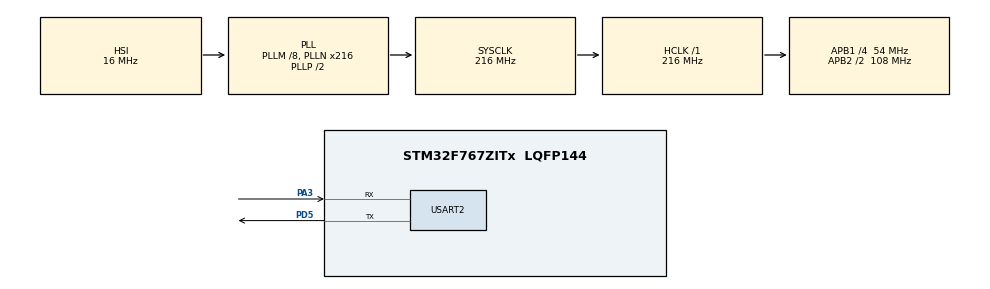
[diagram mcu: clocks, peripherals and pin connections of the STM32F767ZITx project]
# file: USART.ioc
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Dma.Request0=USART2_RX
Dma.USART2_RX.0.Direction=DMA_PERIPH_TO_MEMORY
Dma.USART2_RX.0.FIFOMode=DMA_FIFOMODE_DISABLE
Dma.USART2_RX.0.Instance=DMA1_Stream5
Dma.USART2_RX.0.MemDataAlignment=DMA_MDATAALIGN_BYTE
Dma.USART2_RX.0.MemInc=DMA_MINC_ENABLE
Dma.USART2_RX.0.Mode=DMA_CIRCULAR
Dma.USART2_RX.0.PeriphDataAlignment=DMA_PDATAALIGN_BYTE
Dma.USART2_RX.0.PeriphInc=DMA_PINC_DISABLE
Dma.USART2_RX.0.Priority=DMA_PRIORITY_LOW
Mcu.Family=STM32F7
Mcu.Name=STM32F767ZITx
Mcu.Package=LQFP144
NVIC.DMA1_Stream5_IRQn=true\:0\:0\:false\:false\:true\:false\:true
NVIC.PriorityGroup=NVIC_PRIORITYGROUP_4
NVIC.USART2_IRQn=true\:5\:0\:true\:false\:true\:true\:true
PA3.GPIO_PuPd=GPIO_PULLUP
PA3.Mode=Asynchronous
PA3.Signal=USART2_RX
PD5.Mode=Asynchronous
PD5.Signal=USART2_TX
ProjectManager.HeapSize=0x200
ProjectManager.StackSize=0x400
ProjectManager.TargetToolchain=STM32CubeIDE
RCC.AHBFreq_Value=216000000
RCC.APB1CLKDivider=RCC_HCLK_DIV4
RCC.APB1Freq_Value=54000000
RCC.APB1TimFreq_Value=108000000
RCC.APB2CLKDivider=RCC_HCLK_DIV2
RCC.APB2Freq_Value=108000000
RCC.APB2TimFreq_Value=216000000
RCC.CortexFreq_Value=216000000
RCC.HCLKFreq_Value=216000000
RCC.HSE_VALUE=25000000
RCC.HSI_VALUE=16000000
RCC.LSE_VALUE=32768
RCC.PLLM=8
RCC.PLLN=216
RCC.SYSCLKFreq_VALUE=216000000
RCC.SYSCLKSource=RCC_SYSCLKSOURCE_PLLCLK
RCC.USBFreq_Value=216000000
RCC.VCOOutputFreq_Value=432000000
USART2.VirtualMode-Asynchronous=VM_ASYNC
board=custom

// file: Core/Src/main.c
/* USER CODE BEGIN Header */
/**
  ******************************************************************************
  * @file           : main.c
  * @brief          : Main program body
  ******************************************************************************
  * @attention
  *
  * <h2><center>&copy; Copyright (c) 2021 STMicroelectronics.
  * All rights reserved.</center></h2>
  *
  * This software component is licensed by ST under BSD 3-Clause license,
  * the "License"; You may not use this file except in compliance with the
  * License. You may obtain a copy of the License at:
  *                        opensource.org/licenses/BSD-3-Clause
  *
  ******************************************************************************
  */
/* USER CODE END Header */
#include "main.h"
#include "dma.h"
#include "usart.h"
#include "gpio.h"

/* USER CODE BEGIN PV */
uint8_t receive_buff[255];
/* USER CODE END PV */

void SystemClock_Config(void);

int main(void)
{

  /* MCU Configuration--------------------------------------------------------*/

  /* Reset of all peripherals, Initializes the Flash interface and the Systick. */
  HAL_Init();

  /* Configure the system clock */
  SystemClock_Config();

  /* Initialize all configured peripherals */
  MX_GPIO_Init();
  MX_DMA_Init();
  MX_USART2_UART_Init();

  /* Infinite loop */
  /* USER CODE BEGIN WHILE */
  __HAL_UART_ENABLE_IT(&huart2, UART_IT_IDLE);
  HAL_UART_Receive_DMA(&huart2, (uint8_t*)receive_buff, 255); //transmit 255 byte, from uart to DMA

  while (1)
  {
    /* USER CODE END WHILE */

  }
}

void SystemClock_Config(void)
{
  RCC_OscInitTypeDef RCC_OscInitStruct = {0};
  RCC_ClkInitTypeDef RCC_ClkInitStruct = {0};
  RCC_PeriphCLKInitTypeDef PeriphClkInitStruct = {0};

  /** Configure the main internal regulator output voltage
  */
  __HAL_RCC_PWR_CLK_ENABLE();
  __HAL_PWR_VOLTAGESCALING_CONFIG(PWR_REGULATOR_VOLTAGE_SCALE1);
  /** Initializes the RCC Oscillators according to the specified parameters
  * in the RCC_OscInitTypeDef structure.
  */
  RCC_OscInitStruct.OscillatorType = RCC_OSCILLATORTYPE_HSI;
  RCC_OscInitStruct.HSIState = RCC_HSI_ON;
  RCC_OscInitStruct.HSICalibrationValue = RCC_HSICALIBRATION_DEFAULT;
  RCC_OscInitStruct.PLL.PLLState = RCC_PLL_ON;
  RCC_OscInitStruct.PLL.PLLSource = RCC_PLLSOURCE_HSI;
  RCC_OscInitStruct.PLL.PLLM = 8;
  RCC_OscInitStruct.PLL.PLLN = 216;
  RCC_OscInitStruct.PLL.PLLP = RCC_PLLP_DIV2;
  RCC_OscInitStruct.PLL.PLLQ = 2;
  if (HAL_RCC_OscConfig(&RCC_OscInitStruct) != HAL_OK)
  {
    Error_Handler();
  }
  /** Activate the Over-Drive mode
  */
  if (HAL_PWREx_EnableOverDrive() != HAL_OK)
  {
    Error_Handler();
  }
  /** Initializes the CPU, AHB and APB buses clocks
  */
  RCC_ClkInitStruct.ClockType = RCC_CLOCKTYPE_HCLK|RCC_CLOCKTYPE_SYSCLK
                              |RCC_CLOCKTYPE_PCLK1|RCC_CLOCKTYPE_PCLK2;
  RCC_ClkInitStruct.SYSCLKSource = RCC_SYSCLKSOURCE_PLLCLK;
  RCC_ClkInitStruct.AHBCLKDivider = RCC_SYSCLK_DIV1;
  RCC_ClkInitStruct.APB1CLKDivider = RCC_HCLK_DIV4;
  RCC_ClkInitStruct.APB2CLKDivider = RCC_HCLK_DIV2;

  if (HAL_RCC_ClockConfig(&RCC_ClkInitStruct, FLASH_LATENCY_7) != HAL_OK)
  {
    Error_Handler();
  }
  PeriphClkInitStruct.PeriphClockSelection = RCC_PERIPHCLK_USART2;
  PeriphClkInitStruct.Usart2ClockSelection = RCC_USART2CLKSOURCE_PCLK1;
  if (HAL_RCCEx_PeriphCLKConfig(&PeriphClkInitStruct) != HAL_OK)
  {
    Error_Handler();
  }
}

void Error_Handler(void)
{
  __disable_irq();
  while (1)
  {
  }
}

/************************ (C) COPYRIGHT STMicroelectronics *****END OF FILE****/
